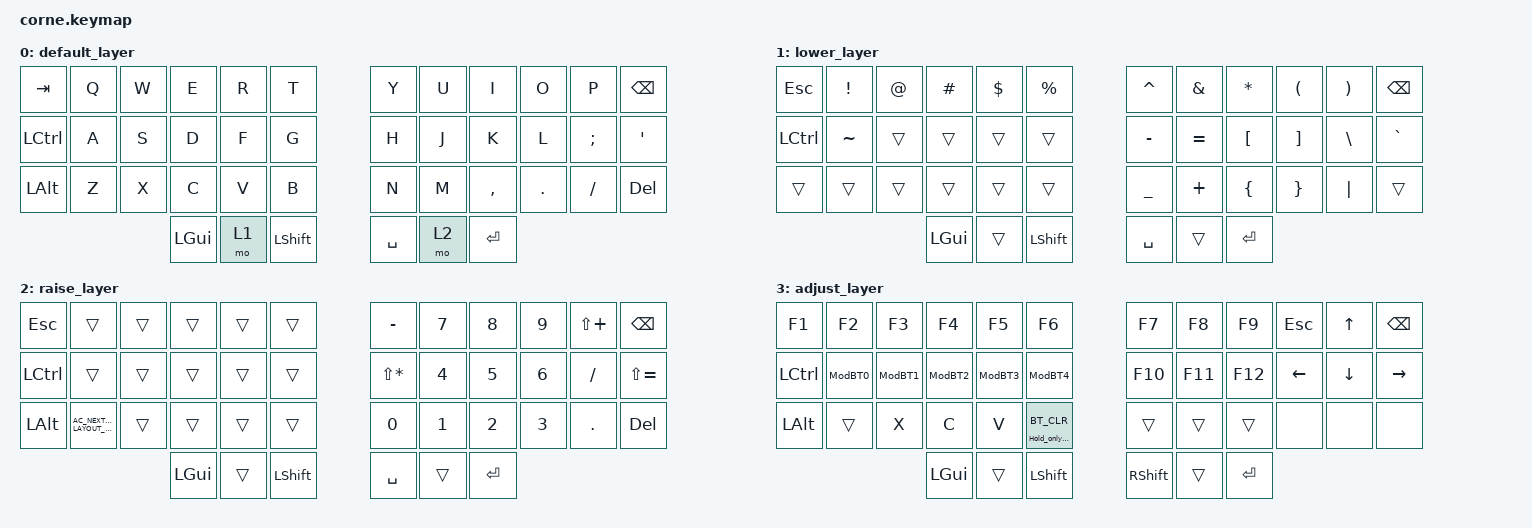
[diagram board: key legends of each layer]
/*
 * Copyright (c) 2020 The ZMK Contributors
 *
 * SPDX-License-Identifier: MIT
 */

#include <behaviors.dtsi>
#include <dt-bindings/zmk/bt.h>
#include <dt-bindings/zmk/keys.h>

/ {
    combos { compatible = "zmk,combos"; };

    behaviors {
        ModBT0: ModBT0 {
            compatible = "zmk,behavior-mod-morph";
            label = "MODBT0";
            bindings = <&bt BT_SEL 0>, <&bt BT_DISC 0>;

            #binding-cells = <0>;
            mods = <(MOD_LCTL)>;
        };

        ModBT1: ModBT1 {
            compatible = "zmk,behavior-mod-morph";
            label = "MODBT1";
            bindings = <&bt BT_SEL 1>, <&bt BT_DISC 1>;

            #binding-cells = <0>;
            mods = <(MOD_LCTL)>;
        };

        ModBT2: ModBT2 {
            compatible = "zmk,behavior-mod-morph";
            label = "MODBT2";
            bindings = <&bt BT_SEL 2>, <&bt BT_DISC 2>;

            #binding-cells = <0>;
            mods = <(MOD_LCTL)>;
        };

        ModBT3: ModBT3 {
            compatible = "zmk,behavior-mod-morph";
            label = "MODBT3";
            bindings = <&bt BT_SEL 3>, <&bt BT_DISC 3>;

            #binding-cells = <0>;
            mods = <(MOD_LCTL)>;
        };

        ModBT4: ModBT4 {
            compatible = "zmk,behavior-mod-morph";
            label = "MODBT4";
            bindings = <&bt BT_SEL 4>, <&bt BT_DISC 4>;

            #binding-cells = <0>;
            mods = <(MOD_LCTL)>;
        };

        Hold_only_BT: Hold_only_BT {
            compatible = "zmk,behavior-hold-tap";
            label = "HOLD_ONLY_BT";
            bindings = <&bt>, <&none>;

            #binding-cells = <2>;
            tapping-term-ms = <2000>;
        };
    };

    keymap {
        compatible = "zmk,keymap";

        default_layer {
            // -----------------------------------------------------------------------------------------
            // |  TAB |  Q  |  W  |  E  |  R  |  T  |   |  Y  |  U   |  I  |  O  |  P  | BSPC |
            // | CTRL |  A  |  S  |  D  |  F  |  G  |   |  H  |  J   |  K  |  L  |  ;  |  '   |
            // | SHFT |  Z  |  X  |  C  |  V  |  B  |   |  N  |  M   |  ,  |  .  |  /  | ESC  |
            //                    | GUI | LWR | SPC |   | ENT | RSE  | ALT |

            bindings = <
&kp TAB    &kp Q  &kp W  &kp E     &kp R  &kp T         &kp Y      &kp U  &kp I      &kp O    &kp P     &kp BSPC
&kp LCTRL  &kp A  &kp S  &kp D     &kp F  &kp G         &kp H      &kp J  &kp K      &kp L    &kp SEMI  &kp SQT
&kp LALT   &kp Z  &kp X  &kp C     &kp V  &kp B         &kp N      &kp M  &kp COMMA  &kp DOT  &kp FSLH  &kp DELETE
                         &kp LGUI  &mo 1  &kp LSHIFT    &kp SPACE  &mo 2  &kp RET
            >;
        };

        lower_layer {
            // -----------------------------------------------------------------------------------------
            // |  TAB |  !  |  @  |  #  |  $  |  %  |   |  ^  |  &  |  *  |  (  |  )  | BSPC |
            // | CTRL |     |     |     |     |     |   |  -  |  =  |  [  |  ]  |  \  |  `   |
            // | SHFT |     |     |     |     |     |   |  _  |  +  |  {  |  }  | "|" |  ~   |
            //                    | GUI |     | SPC |   | ENT |     | ALT |

            bindings = <
&kp ESC    &kp EXCL   &kp AT  &kp HASH  &kp DLLR  &kp PRCNT    &kp CARET  &kp AMPS   &kp ASTRK  &kp LPAR  &kp RPAR  &kp BSPC
&kp LCTRL  &kp TILDE  &trans  &trans    &trans    &trans       &kp MINUS  &kp EQUAL  &kp LBKT   &kp RBKT  &kp BSLH  &kp GRAVE
&trans     &trans     &trans  &trans    &trans    &trans       &kp UNDER  &kp PLUS   &kp LBRC   &kp RBRC  &kp PIPE  &trans
                              &kp LGUI  &trans    &kp LSHFT    &kp SPACE  &trans     &kp RET
            >;
        };

        raise_layer {
            // -----------------------------------------------------------------------------------------
            // |  TAB |  1  |  2  |  3  |  4  |  5  |   |  6  |  7  |  8  |  9  |  0  | BSPC |
            // | BTCLR| BT1 | BT2 | BT3 | BT4 | BT5 |   | LFT | DWN |  UP | RGT |     |      |
            // | SHFT |     |     |     |     |     |   |     |     |     |     |     |      |
            //                    | GUI |     | SPC |   | ENT |     | ALT |

            bindings = <
&kp ESC    &trans                                &trans  &trans    &trans  &trans       &kp MINUS     &kp N7        &kp N8   &kp N9  &kp LS(PLUS)  &kp BACKSPACE
&kp LCTRL  &trans                                &trans  &trans    &trans  &trans       &kp LS(STAR)  &kp NUMBER_4  &kp N5   &kp N6  &kp FSLH      &kp LS(EQUAL)
&kp LALT   &kp C_AC_NEXT_KEYBOARD_LAYOUT_SELECT  &trans  &trans    &trans  &trans       &kp N0        &kp N1        &kp N2   &kp N3  &kp PERIOD    &kp DEL
                                                         &kp LGUI  &trans  &kp LSHFT    &kp SPACE     &trans        &kp RET
            >;
        };

        adjust_layer {
            bindings = <
&kp F1     &kp F2   &kp F3   &kp F4    &kp F5   &kp F6                  &kp F7           &kp F8   &kp F9     &kp ESC   &kp UP    &kp BSPC
&kp LCTRL  &ModBT0  &ModBT1  &ModBT2   &ModBT3  &ModBT4                 &kp F10          &kp F11  &kp F12    &kp LEFT  &kp DOWN  &kp RIGHT
&kp LALT   &trans   &kp X    &kp C     &kp V    &Hold_only_BT BT_CLR    &trans           &trans   &trans     &none     &none     &none
                             &kp LGUI  &trans   &kp LSHFT               &kp RIGHT_SHIFT  &trans   &kp ENTER
            >;
        };
    };

    conditional_layers {
        compatible = "zmk,conditional-layers";

        Trilayer {
            if-layers = <1 2>;
            then-layer = <3>;
        };
    };
};
